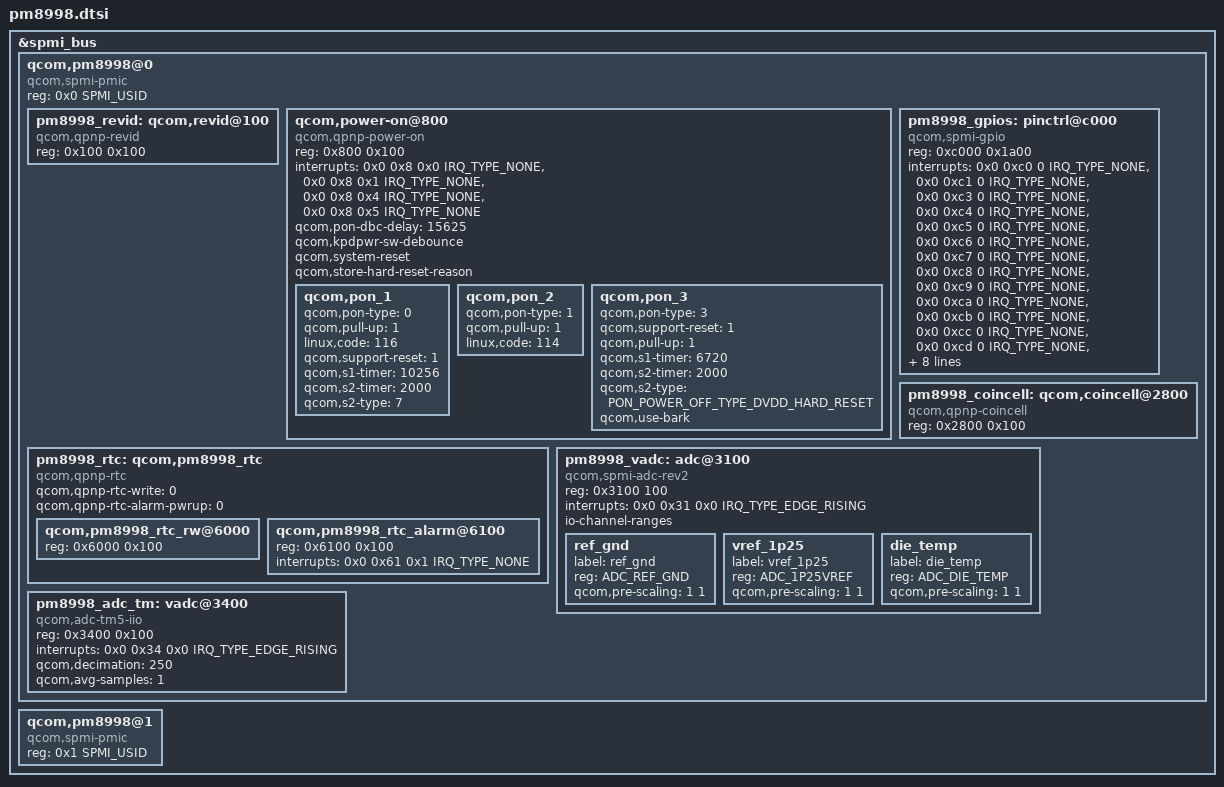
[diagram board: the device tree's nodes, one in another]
/* Copyright (c) 2016-2017, 2019, The Linux Foundation. All rights reserved.
 *
 * This program is free software; you can redistribute it and/or modify
 * it under the terms of the GNU General Public License version 2 and
 * only version 2 as published by the Free Software Foundation.
 *
 * This program is distributed in the hope that it will be useful,
 * but WITHOUT ANY WARRANTY; without even the implied warranty of
 * MERCHANTABILITY or FITNESS FOR A PARTICULAR PURPOSE.  See the
 * GNU General Public License for more details.
 */

#include <dt-bindings/spmi/spmi.h>
#include <dt-bindings/interrupt-controller/irq.h>
#include <dt-bindings/input/qcom,qpnp-power-on.h>
#include <dt-bindings/iio/qcom,spmi-vadc.h>

&spmi_bus {
	qcom,pm8998@0 {
		compatible = "qcom,spmi-pmic";
		reg = <0x0 SPMI_USID>;
		#address-cells = <2>;
		#size-cells = <0>;

		pm8998_revid: qcom,revid@100 {
			compatible = "qcom,qpnp-revid";
			reg = <0x100 0x100>;
		};

		qcom,power-on@800 {
			compatible = "qcom,qpnp-power-on";
			reg = <0x800 0x100>;
			interrupts = <0x0 0x8 0x0 IRQ_TYPE_NONE>,
				     <0x0 0x8 0x1 IRQ_TYPE_NONE>,
				     <0x0 0x8 0x4 IRQ_TYPE_NONE>,
				     <0x0 0x8 0x5 IRQ_TYPE_NONE>;
			interrupt-names = "kpdpwr", "resin",
					"resin-bark", "kpdpwr-resin-bark";
			qcom,pon-dbc-delay = <15625>;
			qcom,kpdpwr-sw-debounce;
			qcom,system-reset;
			qcom,store-hard-reset-reason;

			qcom,pon_1 {
				qcom,pon-type = <0>;
				qcom,pull-up = <1>;
				linux,code = <116>;
				qcom,support-reset = <1>;
				qcom,s1-timer = <10256>;
				qcom,s2-timer = <2000>;
				qcom,s2-type = <7>;
			};

			qcom,pon_2 {
				qcom,pon-type = <1>;
				qcom,pull-up = <1>;
				linux,code = <114>;
			};

			qcom,pon_3 {
				qcom,pon-type = <3>;
				qcom,support-reset = <1>;
				qcom,pull-up = <1>;
				qcom,s1-timer = <6720>;
				qcom,s2-timer = <2000>;
				qcom,s2-type = <PON_POWER_OFF_TYPE_DVDD_HARD_RESET>;
				qcom,use-bark;
			};
		};

		pm8998_gpios: pinctrl@c000 {
			compatible = "qcom,spmi-gpio";
			reg = <0xc000 0x1a00>;
			interrupts = <0x0 0xc0 0 IRQ_TYPE_NONE>,
					<0x0 0xc1 0 IRQ_TYPE_NONE>,
					<0x0 0xc3 0 IRQ_TYPE_NONE>,
					<0x0 0xc4 0 IRQ_TYPE_NONE>,
					<0x0 0xc5 0 IRQ_TYPE_NONE>,
					<0x0 0xc6 0 IRQ_TYPE_NONE>,
					<0x0 0xc7 0 IRQ_TYPE_NONE>,
					<0x0 0xc8 0 IRQ_TYPE_NONE>,
					<0x0 0xc9 0 IRQ_TYPE_NONE>,
					<0x0 0xca 0 IRQ_TYPE_NONE>,
					<0x0 0xcb 0 IRQ_TYPE_NONE>,
					<0x0 0xcc 0 IRQ_TYPE_NONE>,
					<0x0 0xcd 0 IRQ_TYPE_NONE>,
					<0x0 0xcf 0 IRQ_TYPE_NONE>,
					<0x0 0xd0 0 IRQ_TYPE_NONE>,
					<0x0 0xd1 0 IRQ_TYPE_NONE>,
					<0x0 0xd2 0 IRQ_TYPE_NONE>,
					<0x0 0xd4 0 IRQ_TYPE_NONE>,
					<0x0 0xd6 0 IRQ_TYPE_NONE>;
			interrupt-names = "pm8998_gpio1", "pm8998_gpio2",
					"pm8998_gpio4", "pm8998_gpio5",
					"pm8998_gpio6", "pm8998_gpio7",
					"pm8998_gpio8", "pm8998_gpio9",
					"pm8998_gpio10", "pm8998_gpio11",
					"pm8998_gpio12", "pm8998_gpio13",
					"pm8998_gpio14", "pm8998_gpio16",
					"pm8998_gpio17", "pm8998_gpio18",
					"pm8998_gpio19", "pm8998_gpio21",
					"pm8998_gpio23";
			gpio-controller;
			#gpio-cells = <2>;
			qcom,gpios-disallowed = <3 15 20 22 24 25 26>;
		};

		pm8998_coincell: qcom,coincell@2800 {
			compatible = "qcom,qpnp-coincell";
			reg = <0x2800 0x100>;
		};

		pm8998_rtc: qcom,pm8998_rtc {
			compatible = "qcom,qpnp-rtc";
			#address-cells = <1>;
			#size-cells = <1>;
			qcom,qpnp-rtc-write = <0>;
			qcom,qpnp-rtc-alarm-pwrup = <0>;

			qcom,pm8998_rtc_rw@6000 {
				reg = <0x6000 0x100>;
			};
			qcom,pm8998_rtc_alarm@6100 {
				reg = <0x6100 0x100>;
				interrupts = <0x0 0x61 0x1 IRQ_TYPE_NONE>;
			};
		};

		pm8998_vadc: adc@3100 {
			compatible = "qcom,spmi-adc-rev2";
			reg = <0x3100 100>;
			interrupts = <0x0 0x31 0x0 IRQ_TYPE_EDGE_RISING>;
			interrupt-names = "eoc-int-en-set";
			#address-cells = <1>;
			#size-cells = <0>;
			#io-channel-cells = <1>;
			io-channel-ranges;

			ref_gnd {
				label = "ref_gnd";
				reg = <ADC_REF_GND>;
				qcom,pre-scaling = <1 1>;
			};

			vref_1p25 {
				label = "vref_1p25";
				reg = <ADC_1P25VREF>;
				qcom,pre-scaling = <1 1>;
			};

			die_temp {
				label = "die_temp";
				reg = <ADC_DIE_TEMP>;
				qcom,pre-scaling = <1 1>;
			};
		};

		pm8998_adc_tm: vadc@3400 {	
			compatible = "qcom,adc-tm5-iio";
			reg = <0x3400 0x100>;
			interrupts = <0x0 0x34 0x0 IRQ_TYPE_EDGE_RISING>;
			interrupt-names = "eoc-int-en-set";
			qcom,decimation = <250>;
			qcom,avg-samples = <1>;
			#address-cells = <1>;
			#size-cells = <0>;
			#thermal-sensor-cells = <1>;
		};
	};

	qcom,pm8998@1 {
		compatible = "qcom,spmi-pmic";
		reg = <0x1 SPMI_USID>;
		#address-cells = <2>;
		#size-cells = <0>;
	};
};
